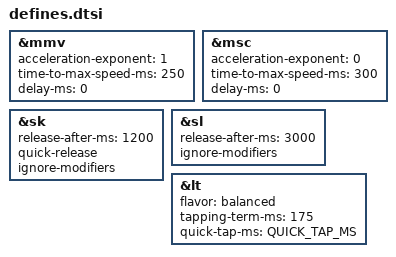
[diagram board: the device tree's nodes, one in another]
#include <behaviors.dtsi>
#include <dt-bindings/zmk/outputs.h>
#include <dt-bindings/zmk/keys.h>
#include <dt-bindings/zmk/bt.h>
#include <dt-bindings/zmk/mouse.h>

/* ── Layer indices ────────────────────────────────────────────────────── */

#define LAYER_Graphite  0
#define LAYER_Racket    1
#define LAYER_Vestnik   2
#define LAYER_Caster    3
#define LAYER_Night     4
#define LAYER_Symbol    5
#define LAYER_Nav       6
#define LAYER_Num       7
#define LAYER_NumMirror 8
#define LAYER_Fn        9
#define LAYER_Mouse     10
#define LAYER_Magic     11

/* ── OS-specific keycodes ─────────────────────────────────────────────── */

#ifndef OPERATING_SYSTEM
#define OPERATING_SYSTEM 1
#endif

#if OPERATING_SYSTEM == 2
    #define _C         LG
    #define _POWER     K_POWER
    #define _HOME      _C(LEFT)
    #define _END       _C(RIGHT)
    #define _LOCK      _C(LC(Q))
    #define _SHUTDOWN  K_POWER
    #define _PASTE     LG(V)
    #define _SCR_FULL  LG(LS(N3))
    #define _SCR_AREA  LG(LS(N4))
#elif OPERATING_SYSTEM == 1
    #define _C         LC
    #define _POWER     C_POWER
    #define _HOME      HOME
    #define _END       END
    #define _LOCK      LG(LS(L))
    #define _SHUTDOWN  LG(LC(LS(Q)))
    #define _PASTE     LC(LS(V))
    #define _SCR_FULL  LG(LS(P))
    #define _SCR_AREA  LG(LS(S))
#elif OPERATING_SYSTEM == 3
    #define _C         LC
    #define _POWER     C_POWER
    #define _HOME      HOME
    #define _END       END
    #define _LOCK      LG(L)
    #define _SHUTDOWN  C_POWER
    #define _PASTE     LC(V)
    #define _SCR_FULL  LG(LS(S))
    #define _SCR_AREA  LG(LS(S))
#endif

#define _SLEEP C_SLEEP

/* ── Keycode aliases (shifted symbols) ────────────────────────────────── */

#ifndef KEYMAP_DRAWER
#undef AMPS
#undef AT
#undef CARET
#undef COLON
#undef DLLR
#undef DQT
#undef EXCL
#undef GT
#undef HASH
#undef LBRC
#undef LPAR
#undef LT
#undef PIPE
#undef PLUS
#undef PRCNT
#undef QMARK
#undef RBRC
#undef RPAR
#undef STAR
#undef TILDE
#undef UNDER
#define AMPS  LS(N7)
#define AT    LS(N2)
#define CARET LS(N6)
#define COLON LS(SEMI)
#define DLLR  LS(N4)
#define DQT   LS(SQT)
#define EXCL  LS(N1)
#define GT    LS(DOT)
#define HASH  LS(N3)
#define LBRC  LS(LBKT)
#define LPAR  LS(N9)
#define LT    LS(COMMA)
#define PIPE  LS(BSLH)
#define PLUS  LS(EQUAL)
#define PRCNT LS(N5)
#define QMARK LS(FSLH)
#define RBRC  LS(RBKT)
#define RPAR  LS(N0)
#define STAR  LS(N8)
#define TILDE LS(GRAVE)
#define UNDER LS(MINUS)
#endif

/* ── Key positions ────────────────────────────────────────────────────── */

#define KEYS_L LT0 LT1 LT2 LT3 LT4  LM0 LM1 LM2 LM3 LM4  LB0 LB1 LB2 LB3 LB4
#define KEYS_R RT0 RT1 RT2 RT3 RT4  RM0 RM1 RM2 RM3 RM4  RB0 RB1 RB2 RB3 RB4
#ifndef THUMBS
#define THUMBS LH2 LH1 RH1 RH2
#endif

#ifndef LH_NONE
#define LH_NONE
#endif
#ifndef RH_NONE
#define RH_NONE
#endif

/* ── Configuration ────────────────────────────────────────────────────── */

#define ALPHA_LAYERS LAYER_Graphite LAYER_Racket LAYER_Vestnik LAYER_Caster LAYER_Night
#define QUICK_TAP_MS 175

#define COMBO_TERM 30
#define COMBO_IDLE 50

#include <zmk-helpers/helper.h>

/* ── Mouse pointing ───────────────────────────────────────────────────── */

#define ZMK_POINTING_DEFAULT_MOVE_VAL 1200
#define ZMK_POINTING_DEFAULT_SCRL_VAL 20

#include <dt-bindings/zmk/pointing.h>

&mmv {
  acceleration-exponent = <1>;
  time-to-max-speed-ms = <250>;
  delay-ms = <0>;
};

&msc {
  acceleration-exponent = <0>;
  time-to-max-speed-ms = <300>;
  delay-ms = <0>;
};

/* ── Global behavior config ──────────────────────────────────────────── */

&sk {
    release-after-ms = <1200>;
    quick-release;
    ignore-modifiers;
};

&sl {
    release-after-ms = <3000>;
    ignore-modifiers;
};

&lt {
    flavor = "balanced";
    tapping-term-ms = <175>;
    quick-tap-ms = <QUICK_TAP_MS>;
};
